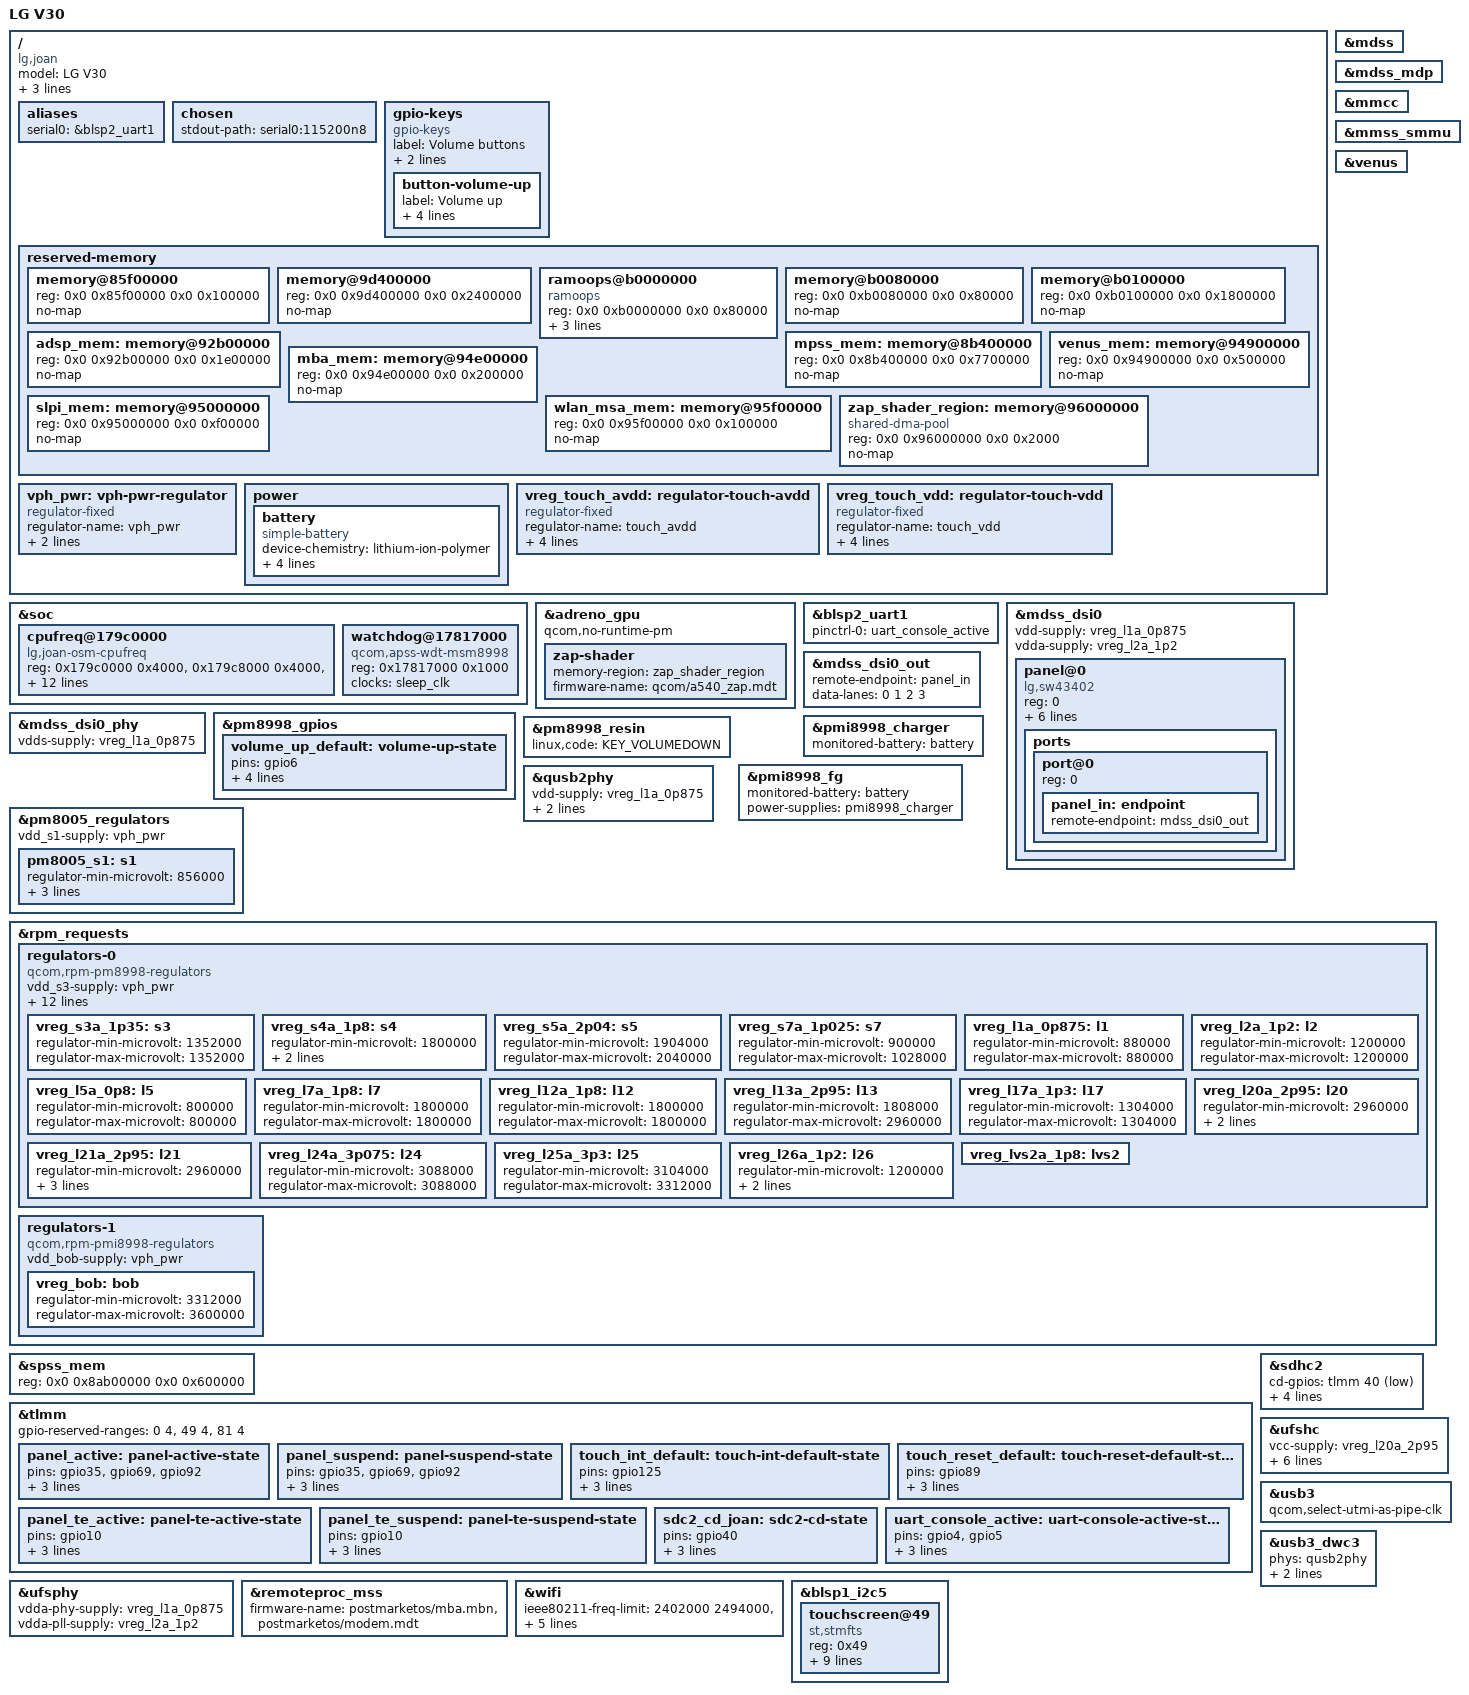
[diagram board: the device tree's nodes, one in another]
// SPDX-License-Identifier: BSD-3-Clause
/*
 * LG V30 (joan) device tree
 *
 * Copyright (c) 2026 GuWolf <admin@guwolf.com>
 */

/dts-v1/;

#include <dt-bindings/pinctrl/qcom,pmic-gpio.h>
#include "msm8998.dtsi"
#include "pm8005.dtsi"
#include "pm8998.dtsi"
#include "pmi8998.dtsi"

/* The firmware carveouts differ from the MSM8998 reference layout. */
/delete-node/ &adsp_mem;
/delete-node/ &mpss_mem;
/delete-node/ &venus_mem;
/delete-node/ &mba_mem;
/delete-node/ &slpi_mem;
/delete-node/ &ipa_fw_mem;
/delete-node/ &ipa_gsi_mem;
/delete-node/ &gpu_mem;
/delete-node/ &wlan_msa_mem;

/ {
	model = "LG V30";
	compatible = "lg,joan", "qcom,msm8998";
	chassis-type = "handset";

	/* Required for LG's bootloader to select this DTB on rev 1.0 hardware. */
	qcom,msm-id = <292 0x20001>;
	qcom,board-id = <0xc08 0>;

	aliases {
		serial0 = &blsp2_uart1;
	};

	chosen {
		stdout-path = "serial0:115200n8";
	};

	gpio-keys {
		compatible = "gpio-keys";
		label = "Volume buttons";
		autorepeat;

		pinctrl-names = "default";
		pinctrl-0 = <&volume_up_default>;

		button-volume-up {
			label = "Volume up";
			gpios = <&pm8998_gpios 6 GPIO_ACTIVE_LOW>;
			linux,code = <KEY_VOLUMEUP>;
			debounce-interval = <15>;
			wakeup-source;
		};
	};

	reserved-memory {
		/* The downstream secure carveout also reserves this 1 MiB gap. */
		memory@85f00000 {
			reg = <0x0 0x85f00000 0x0 0x100000>;
			no-map;
		};

		/* Keep the bootloader-owned splash framebuffer out of normal RAM. */
		memory@9d400000 {
			reg = <0x0 0x9d400000 0x0 0x2400000>;
			no-map;
		};

		/* Match the ramoops region used by the LG recovery kernel. */
		ramoops@b0000000 {
			compatible = "ramoops";
			reg = <0x0 0xb0000000 0x0 0x80000>;
			record-size = <0x40000>;
			console-size = <0x40000>;
			max-reason = <5>;
		};

		/* The remaining half of LG's persistent log region is vendor-owned. */
		memory@b0080000 {
			reg = <0x0 0xb0080000 0x0 0x80000>;
			no-map;
		};

		/* LG firmware may use this framebuffer while handling a crash. */
		memory@b0100000 {
			reg = <0x0 0xb0100000 0x0 0x1800000>;
			no-map;
		};

		adsp_mem: memory@92b00000 {
			reg = <0x0 0x92b00000 0x0 0x1e00000>;
			no-map;
		};

		mpss_mem: memory@8b400000 {
			reg = <0x0 0x8b400000 0x0 0x7700000>;
			no-map;
		};

		venus_mem: memory@94900000 {
			reg = <0x0 0x94900000 0x0 0x500000>;
			no-map;
		};

		mba_mem: memory@94e00000 {
			reg = <0x0 0x94e00000 0x0 0x200000>;
			no-map;
		};

		slpi_mem: memory@95000000 {
			reg = <0x0 0x95000000 0x0 0xf00000>;
			no-map;
		};

		wlan_msa_mem: memory@95f00000 {
			reg = <0x0 0x95f00000 0x0 0x100000>;
			no-map;
		};

		/*
		 * Adreno 540 zap shader staging area.  The A540 on this SoC
		 * refuses to leave secure mode via SECVID_TRUST_CNTL (the
		 * "guessed wrong" case in a5xx_gpu.c), so the zap shader must
		 * be authenticated by the secure world through the PAS (PAS ID
		 * 13) path.  The H930 a540_zap.mdt segments carry the
		 * relocatable flag, so any 0x2000-aligned free physical range
		 * works; 0x96000000 sits directly above the WLAN MSA carveout
		 * and below the first LG firmware region at 0x9d400000.
		 */
		zap_shader_region: memory@96000000 {
			compatible = "shared-dma-pool";
			reg = <0x0 0x96000000 0x0 0x2000>;
			no-map;
		};
	};

	vph_pwr: vph-pwr-regulator {
		compatible = "regulator-fixed";
		regulator-name = "vph_pwr";
		regulator-always-on;
		regulator-boot-on;
	};

	power {
		battery: battery {
			compatible = "simple-battery";
			device-chemistry = "lithium-ion-polymer";
			charge-full-design-microamp-hours = <3300000>;
			voltage-min-design-microvolt = <3200000>;
			voltage-max-design-microvolt = <4400000>;
			constant-charge-voltage-max-microvolt = <4400000>;
		};
	};
};

&soc {
	cpufreq@179c0000 {
		compatible = "lg,joan-osm-cpufreq";
		reg = <0x179c0000 0x4000>,
		      <0x179c8000 0x4000>,
		      <0x179c4000 0x4000>,
		      <0x17914800 0x800>,
		      <0x17814800 0x800>,
		      <0x179d1000 0x1000>,
		      <0x17912000 0x1000>,
		      <0x17812000 0x1000>;
		reg-names = "osm", "power-cprh", "performance-cprh",
			    "power-acd", "performance-acd", "apcs-common",
			    "power-saw", "performance-saw";

		clocks = <&gcc GCC_HMSS_RBCPR_CLK>,
			 <&gcc HMSS_GPLL0_CLK_SRC>,
			 <&rpmcc RPM_SMD_XO_CLK_SRC>;
		clock-names = "cpr", "aux", "xo";

		nvmem-cells = <&cpr_fuse_row38>, <&cpr_fuse_row39>,
			      <&cpr_fuse_row67>, <&cpr_fuse_row68>,
			      <&cpr_fuse_row69>, <&cpr_fuse_row70>,
			      <&cpr_fuse_row71>, <&cpr_fuse_row100>;
		nvmem-cell-names = "row38", "row39", "row67", "row68",
				   "row69", "row70", "row71", "row100";
	};

	watchdog@17817000 {
		compatible = "qcom,apss-wdt-msm8998", "qcom,kpss-wdt";
		reg = <0x17817000 0x1000>;
		clocks = <&sleep_clk>;
	};
};

/*
 * Headless GPU-only bring-up: enable the Adreno 540 while the entire display
 * chain (mdss / mdss_mdp / mdss_dsi0 / mdss_dsi0_phy) stays disabled. The GPU
 * must therefore not wait for the mdss component master, which is why msm has
 * to be loaded with separate_gpu_kms=1; see notes/joan-gpu-headless.md. The GPU
 * then registers its own DRM device with DRIVER_RENDER and exposes
 * /dev/dri/renderD128 for surfaceless EGL, with no KMS and no /dev/fb*.
 *
 * Do NOT enable &venus (video-codec@cc00000) together with this. Enabling Venus
 * made mainline 6.18.49-r88 hard-reset during boot: udev autoloads venus-core
 * from the DT modalias, then qcom_scm_pas_auth_and_reset() resets the
 * TrustZone/PAS path. Venus must stay disabled until that is root-caused.
 *
 * VDD_GFX (pm8005_s1) is already marked regulator-always-on above, and
 * adreno_smmu / gpucc / gcc / rpmpd are all enabled by default in msm8998.dtsi,
 * so status is the only change the GPU node itself needs.
 */
&adreno_gpu {
	status = "okay";

	/*
	 * Powering the GPU (and, with it, the GPU's SMMU) down and back up
	 * again is not lossless on joan: the GPU comes back unable to
	 * translate its addresses, faults on everything it touches, and the
	 * hangcheck recovery that follows can wedge the SoC -- a completely
	 * silent hard reset that the bootloader then reports as
	 * bootreasoncode 0x20.  Reproduces with four concurrent headless
	 * Chromium instances and disappears as soon as the GPU is kept
	 * runtime-resumed, so opt this board out of GPU runtime PM.
	 */
	qcom,no-runtime-pm;

	/*
	 * LG's own kernel loads the a540_zap shader for this GPU through PAS
	 * (qcom,kgsl-hyp, pas-id 13, firmware-name "a540_zap"), so the A540 on
	 * joan does require the zap shader: the fallback path that writes
	 * RBBM_SECVID_TRUST_CNTL directly is rejected by the secure world and
	 * ends in an RCU stall as soon as the render node is opened.
	 * H930/H932 zap binaries are interchangeable on joan (only H932 has
	 * its own signing keys); the H930 set is installed as
	 * /lib/firmware/qcom/a540_zap.mdt plus .b00/.b01/.b02.
	 */
	zap-shader {
		memory-region = <&zap_shader_region>;
		firmware-name = "qcom/a540_zap.mdt";
	};
};

&blsp2_uart1 {
	pinctrl-names = "default";
	pinctrl-0 = <&uart_console_active>;
	status = "okay";
};

&mdss_dsi0 {
	#address-cells = <1>;
	#size-cells = <0>;
	/*
	 * 显示链重新启用（2026-10-28）。此前为 bring-up 诊断整条关闭，
	 * 现在要验证 SW43402 面板能否出图。
	 */
	status = "okay";

	vdd-supply = <&vreg_l1a_0p875>;
	vdda-supply = <&vreg_l2a_1p2>;

	panel@0 {
		compatible = "lg,sw43402";
		reg = <0>;

		reset-gpios = <&tlmm 35 GPIO_ACTIVE_HIGH>;
		vddio-gpios = <&tlmm 92 GPIO_ACTIVE_HIGH>;
		vpnl-gpios = <&tlmm 69 GPIO_ACTIVE_HIGH>;
		disp-te-gpios = <&tlmm 10 GPIO_ACTIVE_HIGH>;

		pinctrl-names = "default", "sleep";
		pinctrl-0 = <&panel_active &panel_te_active>;
		pinctrl-1 = <&panel_suspend &panel_te_suspend>;

		ports {
			#address-cells = <1>;
			#size-cells = <0>;

			port@0 {
				reg = <0>;

				panel_in: endpoint {
					remote-endpoint = <&mdss_dsi0_out>;
				};
			};
		};
	};
};

&mdss_dsi0_out {
	remote-endpoint = <&panel_in>;
	data-lanes = <0 1 2 3>;
};

&mdss_dsi0_phy {
	vdds-supply = <&vreg_l1a_0p875>;
	status = "okay";
};

&mdss {
	status = "okay";
};

&mdss_mdp {
	status = "okay";
};

&mmcc {
	status = "okay";
};

&mmss_smmu {
	status = "okay";
};

/*
 * Venus 硬件编解码（2026-10-10 重开）：DT 节点启用，但模块在设备侧由
 * /etc/modprobe.d/blacklist-venus.conf 挡住，不让 udev 在启动期自动 probe
 * —— r88 曾因自动 probe 触发 qcom_scm_pas_auth_and_reset() 造成启动期硬复位，
 * 见 note.md §16。人工 modprobe 时才真正上电。
 */
&venus {
	status = "okay";
};

&pm8998_gpios {
	volume_up_default: volume-up-state {
		pins = "gpio6";
		function = "normal";
		bias-pull-up;
		input-enable;
		qcom,drive-strength = <PMIC_GPIO_STRENGTH_NO>;
	};
};

&pm8998_resin {
	linux,code = <KEY_VOLUMEDOWN>;
	status = "okay";
};

&pmi8998_charger {
	status = "okay";
	monitored-battery = <&battery>;
};

&pmi8998_fg {
	status = "okay";
	monitored-battery = <&battery>;
	power-supplies = <&pmi8998_charger>;
};

&pm8005_regulators {
	vdd_s1-supply = <&vph_pwr>;

	pm8005_s1: s1 {
		/*
		 * VDD_GFX, required before the GPU GX power domain can enable.
		 *
		 * mainline has no GPU CPR and the Adreno driver never calls
		 * regulator_set_voltage() on this rail: the GPU node has no
		 * vdd-supply, so msm_gpu binds a dummy regulator ("supply vdd not
		 * found, using dummy regulator") and only ever enables/disables it.
		 * With a min/max *range* the regulator core also leaves the rail
		 * alone, so VDD_GFX stayed at whatever LG's bootloader programmed:
		 * 752 mV.
		 *
		 * 752 mV is far below the vendor value for the top GPU OPP
		 * (964 mV @ 710 MHz per the msm8998 kgsl OPP table).  With the
		 * GPU kept runtime-resumed (see the adreno_gpu node above) the
		 * rail no longer resets the device, but 752 mV is a pinched
		 * setpoint: sustained 4x chromium 1080p load produces sporadic
		 * SMMU context faults.
		 *
		 * Pinning min == max makes machine_constraints_voltage() push
		 * the rail to that setpoint at probe time -- the intended
		 * "hack until we rig up the gpu consumer" that pm8005_s1's
		 * always-on comment refers to.
		 *
		 * 2026-10-08 full 4 mV-step sweep (GPU pinned at 710 MHz,
		 * 4x chromium 1080p capture per round, kernel with the GPU
		 * kept resumed via qcom,no-runtime-pm):
		 *   752 mV: SMMU faults, sporadic
		 *   776 mV: SMMU faults from round 1
		 *   792 mV: SMMU faults, first burst at round 14
		 *   796 mV: SMMU faults at rounds 7 and 13
		 *   800 mV: SMMU faults at rounds 8 and 10
		 *   804 mV: clean over 15 rounds -- lowest fault-free setpoint
		 *   856 mV: clean over 15 + 30 rounds -- released setpoint
		 *   964 mV: clean, the vendor value
		 *
		 * The clean/unhealthy edge is a single 4 mV step (800 -> 804),
		 * so the released setpoint keeps 52 mV of margin above the
		 * measured floor while sitting 108 mV below the vendor value.
		 * Faults are bursty and can hide for ~14 rounds: re-run the
		 * 30-round sweep before lowering this setpoint, and fall back
		 * to 964000 if 856000 ever misbehaves.
		 */
		regulator-min-microvolt = <856000>;
		regulator-max-microvolt = <856000>;
		regulator-enable-ramp-delay = <500>;
		regulator-always-on;
	};
};

&qusb2phy {
	vdd-supply = <&vreg_l1a_0p875>;
	vdda-pll-supply = <&vreg_l12a_1p8>;
	vdda-phy-dpdm-supply = <&vreg_l24a_3p075>;
	status = "okay";
};

&rpm_requests {
	regulators-0 {
		compatible = "qcom,rpm-pm8998-regulators";

		vdd_s3-supply = <&vph_pwr>;
		vdd_s4-supply = <&vph_pwr>;
		vdd_s5-supply = <&vph_pwr>;
		vdd_s7-supply = <&vph_pwr>;
		vdd_l1_l27-supply = <&vreg_s7a_1p025>;
		vdd_l2_l8_l17-supply = <&vreg_s3a_1p35>;
		vdd_l4_l5-supply = <&vreg_s7a_1p025>;
		vdd_l7_l12_l14_l15-supply = <&vreg_s5a_2p04>;
		vdd_l10_l23_l25-supply = <&vreg_bob>;
		vdd_l13_l19_l21-supply = <&vreg_bob>;
		vdd_l20_l24-supply = <&vreg_bob>;
		vdd_l26-supply = <&vreg_s3a_1p35>;
		vdd_lvs1_lvs2-supply = <&vreg_s4a_1p8>;

		vreg_s3a_1p35: s3 {
			regulator-min-microvolt = <1352000>;
			regulator-max-microvolt = <1352000>;
		};

		vreg_s4a_1p8: s4 {
			regulator-min-microvolt = <1800000>;
			regulator-max-microvolt = <1800000>;
			regulator-allow-set-load;
		};

		vreg_s5a_2p04: s5 {
			regulator-min-microvolt = <1904000>;
			regulator-max-microvolt = <2040000>;
		};

		vreg_s7a_1p025: s7 {
			regulator-min-microvolt = <900000>;
			regulator-max-microvolt = <1028000>;
		};

		vreg_l1a_0p875: l1 {
			regulator-min-microvolt = <880000>;
			regulator-max-microvolt = <880000>;
		};

		vreg_l2a_1p2: l2 {
			regulator-min-microvolt = <1200000>;
			regulator-max-microvolt = <1200000>;
		};

		vreg_l5a_0p8: l5 {
			regulator-min-microvolt = <800000>;
			regulator-max-microvolt = <800000>;
		};

		vreg_l7a_1p8: l7 {
			regulator-min-microvolt = <1800000>;
			regulator-max-microvolt = <1800000>;
		};

		vreg_l12a_1p8: l12 {
			regulator-min-microvolt = <1800000>;
			regulator-max-microvolt = <1800000>;
		};

		vreg_l13a_2p95: l13 {
			regulator-min-microvolt = <1808000>;
			regulator-max-microvolt = <2960000>;
		};

		vreg_l17a_1p3: l17 {
			regulator-min-microvolt = <1304000>;
			regulator-max-microvolt = <1304000>;
		};

		vreg_l20a_2p95: l20 {
			regulator-min-microvolt = <2960000>;
			regulator-max-microvolt = <2960000>;
			regulator-allow-set-load;
		};

		vreg_l21a_2p95: l21 {
			regulator-min-microvolt = <2960000>;
			regulator-max-microvolt = <2960000>;
			regulator-system-load = <800000>;
			regulator-allow-set-load;
		};

		vreg_l24a_3p075: l24 {
			regulator-min-microvolt = <3088000>;
			regulator-max-microvolt = <3088000>;
		};

		vreg_l25a_3p3: l25 {
			regulator-min-microvolt = <3104000>;
			regulator-max-microvolt = <3312000>;
		};

		vreg_l26a_1p2: l26 {
			regulator-min-microvolt = <1200000>;
			regulator-max-microvolt = <1200000>;
			regulator-allow-set-load;
		};

		vreg_lvs2a_1p8: lvs2 { };
	};

	regulators-1 {
		compatible = "qcom,rpm-pmi8998-regulators";
		vdd_bob-supply = <&vph_pwr>;

		vreg_bob: bob {
			regulator-min-microvolt = <3312000>;
			regulator-max-microvolt = <3600000>;
		};
	};
};

&spss_mem {
	reg = <0x0 0x8ab00000 0x0 0x600000>;
};

&tlmm {
	gpio-reserved-ranges = <0 4>, <49 4>, <81 4>;

	panel_active: panel-active-state {
		pins = "gpio35", "gpio69", "gpio92";
		function = "gpio";
		drive-strength = <8>;
		bias-disable;
	};

	panel_suspend: panel-suspend-state {
		pins = "gpio35", "gpio69", "gpio92";
		function = "gpio";
		drive-strength = <2>;
		bias-pull-down;
	};

	/* 触摸：中断（gpio125，低有效）与复位（gpio89，低有效） */
	touch_int_default: touch-int-default-state {
		pins = "gpio125";
		function = "gpio";
		drive-strength = <2>;
		bias-pull-up;
	};

	touch_reset_default: touch-reset-default-state {
		pins = "gpio89";
		function = "gpio";
		drive-strength = <2>;
		bias-pull-up;
	};

	panel_te_active: panel-te-active-state {
		pins = "gpio10";
		function = "mdp_vsync_a";
		drive-strength = <2>;
		bias-pull-down;
	};

	panel_te_suspend: panel-te-suspend-state {
		pins = "gpio10";
		function = "mdp_vsync_a";
		drive-strength = <2>;
		bias-pull-down;
	};

	sdc2_cd_joan: sdc2-cd-state {
		pins = "gpio40";
		function = "gpio";
		bias-pull-up;
		drive-strength = <2>;
	};

	uart_console_active: uart-console-active-state {
		pins = "gpio4", "gpio5";
		function = "blsp_uart8_a";
		drive-strength = <2>;
		bias-disable;
	};
};

&sdhc2 {
	status = "okay";
	cd-gpios = <&tlmm 40 GPIO_ACTIVE_LOW>;

	vmmc-supply = <&vreg_l21a_2p95>;
	vqmmc-supply = <&vreg_l13a_2p95>;

	pinctrl-names = "default", "sleep";
	pinctrl-0 = <&sdc2_on &sdc2_cd_joan>;
	pinctrl-1 = <&sdc2_off &sdc2_cd_joan>;
};

&ufshc {
	vcc-supply = <&vreg_l20a_2p95>;
	vccq-supply = <&vreg_l26a_1p2>;
	vccq2-supply = <&vreg_s4a_1p8>;
	vdd-hba-supply = <&vreg_l26a_1p2>;
	vcc-max-microamp = <750000>;
	vccq-max-microamp = <560000>;
	vccq2-max-microamp = <750000>;
	status = "okay";
};

&ufsphy {
	vdda-phy-supply = <&vreg_l1a_0p875>;
	vdda-pll-supply = <&vreg_l2a_1p2>;
	status = "okay";
};

&usb3 {
	qcom,select-utmi-as-pipe-clk;
	status = "okay";
};

&usb3_dwc3 {
	phys = <&qusb2phy>;
	phy-names = "usb2-phy";
	maximum-speed = "high-speed";
	dr_mode = "peripheral";
};

&remoteproc_mss {
	status = "okay";
	firmware-name = "postmarketos/mba.mbn",
			"postmarketos/modem.mdt";
};

&wifi {
	status = "okay";
	ieee80211-freq-limit = <2402000 2494000>,
				   <5170000 5835000>;

	vdd-0.8-cx-mx-supply = <&vreg_l5a_0p8>;
	vdd-1.8-xo-supply = <&vreg_l7a_1p8>;
	vdd-1.3-rfa-supply = <&vreg_l17a_1p3>;
	vdd-3.3-ch0-supply = <&vreg_l25a_3p3>;
};

/*
 * 触摸第 2 步（2026-10-28）：加上供电与触摸节点。
 *
 * 第 1 步已经实测：只启用 I2C5 时总线上扫不到任何设备；
 * 用 GPIO 拉起 TLMM 85 / 86 后，0x49 立刻有 ACK。
 * 所以这两个 GPIO 是触摸芯片的电源开关，必须由 DTS 描述成 regulator。
 *
 * 芯片：STMicro FingerTipS FTS3670
 *   总线  ：BLSP1 QUP5（i2c-0），地址 0x49
 *   中断  ：TLMM 125，低有效
 *   复位  ：TLMM 89，低有效
 *   avdd  ：TLMM 85（3.3V 负载开关）
 *   vdd   ：TLMM 86（1.8V 负载开关）
 */

/ {
	vreg_touch_avdd: regulator-touch-avdd {
		compatible = "regulator-fixed";
		regulator-name = "touch_avdd";
		regulator-min-microvolt = <3300000>;
		regulator-max-microvolt = <3300000>;
		gpio = <&tlmm 85 GPIO_ACTIVE_HIGH>;
		enable-active-high;
	};

	vreg_touch_vdd: regulator-touch-vdd {
		compatible = "regulator-fixed";
		regulator-name = "touch_vdd";
		regulator-min-microvolt = <1800000>;
		regulator-max-microvolt = <1800000>;
		gpio = <&tlmm 86 GPIO_ACTIVE_HIGH>;
		enable-active-high;
	};
};

&blsp1_i2c5 {
	status = "okay";

	touchscreen@49 {
		/* 先用主线上游的 compatible，看驱动能 probe 到哪一步 */
		compatible = "st,stmfts";
		reg = <0x49>;

		interrupt-parent = <&tlmm>;
		interrupts = <125 IRQ_TYPE_LEVEL_LOW>;

		vdd-supply = <&vreg_touch_vdd>;
		avdd-supply = <&vreg_touch_avdd>;

		reset-gpios = <&tlmm 89 GPIO_ACTIVE_LOW>;

		touchscreen-size-x = <1440>;
		touchscreen-size-y = <2880>;

		pinctrl-names = "default";
		pinctrl-0 = <&touch_int_default &touch_reset_default>;
	};
};
